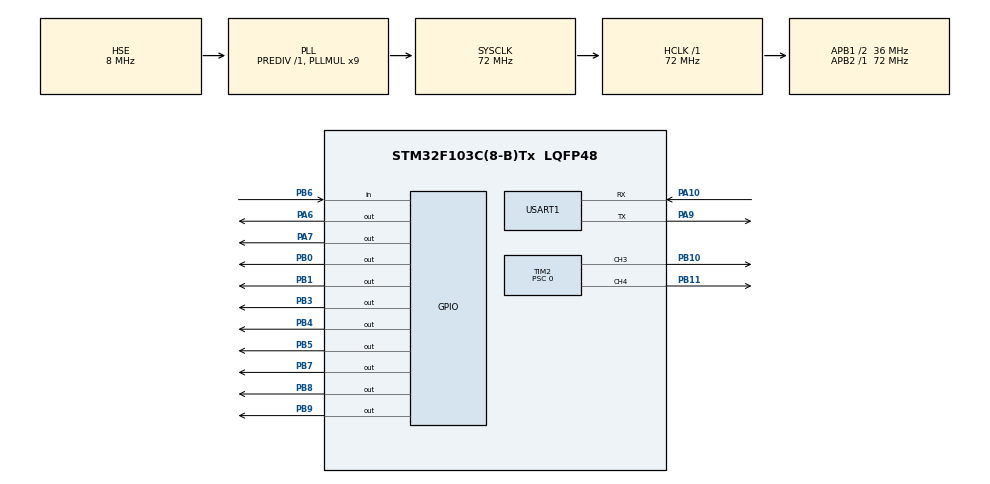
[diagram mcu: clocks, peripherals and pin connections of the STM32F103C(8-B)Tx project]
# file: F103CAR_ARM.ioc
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Mcu.Family=STM32F1
Mcu.Name=STM32F103C(8-B)Tx
Mcu.Package=LQFP48
NVIC.PriorityGroup=NVIC_PRIORITYGROUP_4
NVIC.TIM4_IRQn=true\:0\:0\:false\:false\:true\:false\:true
NVIC.TimeBase=TIM4_IRQn
NVIC.TimeBaseIP=TIM4
PA10.Mode=Asynchronous
PA10.Signal=USART1_RX
PA13.Mode=Serial_Wire
PA13.Signal=SYS_JTMS-SWDIO
PA14.Mode=Serial_Wire
PA14.Signal=SYS_JTCK-SWCLK
PA6.Signal=GPIO_Output
PA7.Signal=GPIO_Output
PA9.Mode=Asynchronous
PA9.Signal=USART1_TX
PB0.Signal=GPIO_Output
PB1.Signal=GPIO_Output
PB10.Signal=S_TIM2_CH3
PB11.Signal=S_TIM2_CH4
PB3.Signal=GPIO_Output
PB4.Signal=GPIO_Output
PB5.Signal=GPIO_Output
PB6.Signal=GPIO_Input
PB7.Signal=GPIO_Output
PB8.Signal=GPIO_Output
PB9.Signal=GPIO_Output
PC14-OSC32_IN.Mode=LSE-External-Oscillator
PC14-OSC32_IN.Signal=RCC_OSC32_IN
PC15-OSC32_OUT.Mode=LSE-External-Oscillator
PC15-OSC32_OUT.Signal=RCC_OSC32_OUT
PD0-OSC_IN.Mode=HSE-External-Oscillator
PD0-OSC_IN.Signal=RCC_OSC_IN
PD1-OSC_OUT.Mode=HSE-External-Oscillator
PD1-OSC_OUT.Signal=RCC_OSC_OUT
ProjectManager.HeapSize=0x200
ProjectManager.StackSize=0x400
ProjectManager.TargetToolchain=MDK-ARM V5
RCC.AHBFreq_Value=72000000
RCC.APB1CLKDivider=RCC_HCLK_DIV2
RCC.APB1Freq_Value=36000000
RCC.APB1TimFreq_Value=72000000
RCC.APB2Freq_Value=72000000
RCC.APB2TimFreq_Value=72000000
RCC.HCLKFreq_Value=72000000
RCC.PLLMUL=RCC_PLL_MUL9
RCC.PLLSourceVirtual=RCC_PLLSOURCE_HSE
RCC.SYSCLKFreq_VALUE=72000000
RCC.SYSCLKSource=RCC_SYSCLKSOURCE_PLLCLK
RCC.USBFreq_Value=72000000
SH.S_TIM2_CH3.0=TIM2_CH3,PWM Generation3 CH3
SH.S_TIM2_CH4.0=TIM2_CH4,PWM Generation4 CH4
TIM2.Channel-PWM\ Generation3\ CH3=TIM_CHANNEL_3
TIM2.Channel-PWM\ Generation4\ CH4=TIM_CHANNEL_4
TIM2.Period=4095
TIM2.Prescaler=0
TIM3.Period=65535
TIM3.Prescaler=72-1
USART1.VirtualMode=VM_ASYNC
VP_SYS_VS_tim4.Mode=TIM4
VP_TIM3_VS_ClockSourceINT.Mode=Internal
board=custom

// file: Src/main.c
/* USER CODE BEGIN Header */
/**
  ******************************************************************************
  * @file           : main.c
  * @brief          : Main program body
  ******************************************************************************
  * @attention
  *
  * <h2><center>&copy; Copyright (c) 2019 STMicroelectronics.
  * All rights reserved.</center></h2>
  *
  * This software component is licensed by ST under BSD 3-Clause license,
  * the "License"; You may not use this file except in compliance with the
  * License. You may obtain a copy of the License at:
  *                        opensource.org/licenses/BSD-3-Clause
  *
  ******************************************************************************
  */
/* USER CODE END Header */

#include "main.h"
#include "tim.h"
#include "usart.h"
#include "gpio.h"

void SystemClock_Config(void);

/* USER CODE BEGIN 0 */
#include "ps2.h"
#include "pca9685.h"
#include "servo.h"
#include "robot.h"
#include "usart.h"
/* USER CODE END 0 */

int main(void)
{

  /* MCU Configuration--------------------------------------------------------*/

  /* Reset of all peripherals, Initializes the Flash interface and the Systick. */
  HAL_Init();

  /* Configure the system clock */
  SystemClock_Config();

  /* Initialize all configured peripherals */
  MX_GPIO_Init();
  MX_TIM2_Init();
  MX_TIM3_Init();
  MX_USART1_UART_Init();
  /* USER CODE BEGIN 2 */
PS2_Init();
RobotInit();
  /* USER CODE END 2 */

  /* Infinite loop */
  while (1)
  {
		//PS2_Test();
		RobotTest();
		delay_ms(1);
  }
}

void SystemClock_Config(void)
{
  RCC_OscInitTypeDef RCC_OscInitStruct = {0};
  RCC_ClkInitTypeDef RCC_ClkInitStruct = {0};

  /** Initializes the CPU, AHB and APB busses clocks
  */
  RCC_OscInitStruct.OscillatorType = RCC_OSCILLATORTYPE_HSE;
  RCC_OscInitStruct.HSEState = RCC_HSE_ON;
  RCC_OscInitStruct.HSEPredivValue = RCC_HSE_PREDIV_DIV1;
  RCC_OscInitStruct.HSIState = RCC_HSI_ON;
  RCC_OscInitStruct.PLL.PLLState = RCC_PLL_ON;
  RCC_OscInitStruct.PLL.PLLSource = RCC_PLLSOURCE_HSE;
  RCC_OscInitStruct.PLL.PLLMUL = RCC_PLL_MUL9;
  if (HAL_RCC_OscConfig(&RCC_OscInitStruct) != HAL_OK)
  {
    Error_Handler();
  }
  /** Initializes the CPU, AHB and APB busses clocks
  */
  RCC_ClkInitStruct.ClockType = RCC_CLOCKTYPE_HCLK|RCC_CLOCKTYPE_SYSCLK
                              |RCC_CLOCKTYPE_PCLK1|RCC_CLOCKTYPE_PCLK2;
  RCC_ClkInitStruct.SYSCLKSource = RCC_SYSCLKSOURCE_PLLCLK;
  RCC_ClkInitStruct.AHBCLKDivider = RCC_SYSCLK_DIV1;
  RCC_ClkInitStruct.APB1CLKDivider = RCC_HCLK_DIV2;
  RCC_ClkInitStruct.APB2CLKDivider = RCC_HCLK_DIV1;

  if (HAL_RCC_ClockConfig(&RCC_ClkInitStruct, FLASH_LATENCY_2) != HAL_OK)
  {
    Error_Handler();
  }
}

void HAL_TIM_PeriodElapsedCallback(TIM_HandleTypeDef *htim)
{
  if (htim->Instance == TIM4) {
    HAL_IncTick();
  }
}

void Error_Handler(void)
{
}

/************************ (C) COPYRIGHT STMicroelectronics *****END OF FILE****/
